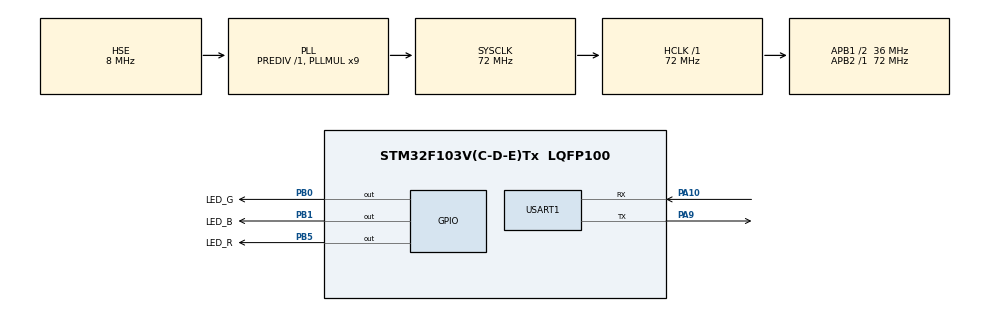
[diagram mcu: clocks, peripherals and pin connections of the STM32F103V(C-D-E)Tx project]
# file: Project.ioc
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Dma.Request0=USART1_RX
Dma.USART1_RX.0.Direction=DMA_PERIPH_TO_MEMORY
Dma.USART1_RX.0.Instance=DMA1_Channel5
Dma.USART1_RX.0.MemDataAlignment=DMA_MDATAALIGN_BYTE
Dma.USART1_RX.0.MemInc=DMA_MINC_ENABLE
Dma.USART1_RX.0.Mode=DMA_NORMAL
Dma.USART1_RX.0.PeriphDataAlignment=DMA_PDATAALIGN_BYTE
Dma.USART1_RX.0.PeriphInc=DMA_PINC_DISABLE
Dma.USART1_RX.0.Priority=DMA_PRIORITY_LOW
FREERTOS.Tasks01=defaultTask,0,128,StartDefaultTask,Default,NULL,Dynamic,NULL,NULL
Mcu.Family=STM32F1
Mcu.Name=STM32F103V(C-D-E)Tx
Mcu.Package=LQFP100
NVIC.DMA1_Channel5_IRQn=true\:5\:0\:false\:false\:true\:true\:false\:true\:true
NVIC.PriorityGroup=NVIC_PRIORITYGROUP_4
NVIC.TIM6_IRQn=true\:15\:0\:false\:false\:true\:false\:false\:true\:true
NVIC.TIM7_IRQn=true\:5\:0\:false\:false\:true\:true\:true\:true\:true
NVIC.TimeBase=TIM6_IRQn
NVIC.TimeBaseIP=TIM6
NVIC.USART1_IRQn=true\:5\:0\:false\:false\:true\:true\:true\:true\:true
OSC_IN.Mode=HSE-External-Oscillator
OSC_IN.Signal=RCC_OSC_IN
OSC_OUT.Mode=HSE-External-Oscillator
OSC_OUT.Signal=RCC_OSC_OUT
PA10.Mode=Asynchronous
PA10.Signal=USART1_RX
PA13.Mode=Serial_Wire
PA13.Signal=SYS_JTMS-SWDIO
PA14.Mode=Serial_Wire
PA14.Signal=SYS_JTCK-SWCLK
PA9.Mode=Asynchronous
PA9.Signal=USART1_TX
PB0.GPIO_Label=LED_G
PB0.PinState=GPIO_PIN_SET
PB0.Signal=GPIO_Output
PB1.GPIO_Label=LED_B
PB1.PinState=GPIO_PIN_SET
PB1.Signal=GPIO_Output
PB5.GPIO_Label=LED_R
PB5.PinState=GPIO_PIN_SET
PB5.Signal=GPIO_Output
ProjectManager.HeapSize=0x200
ProjectManager.StackSize=0x400
ProjectManager.TargetToolchain=CMake
RCC.AHBFreq_Value=72000000
RCC.APB1CLKDivider=RCC_HCLK_DIV2
RCC.APB1Freq_Value=36000000
RCC.APB1TimFreq_Value=72000000
RCC.APB2Freq_Value=72000000
RCC.APB2TimFreq_Value=72000000
RCC.HCLKFreq_Value=72000000
RCC.PLLMUL=RCC_PLL_MUL9
RCC.PLLSourceVirtual=RCC_PLLSOURCE_HSE
RCC.SYSCLKFreq_VALUE=72000000
RCC.SYSCLKSource=RCC_SYSCLKSOURCE_PLLCLK
RCC.USBFreq_Value=72000000
TIM7.AutoReloadPreload=TIM_AUTORELOAD_PRELOAD_ENABLE
TIM7.Period=1000-1
TIM7.Prescaler=72-1
USART1.VirtualMode=VM_ASYNC
VP_FREERTOS_VS_CMSIS_V1.Mode=CMSIS_V1
VP_SYS_VS_tim6.Mode=TIM6
VP_TIM7_VS_ClockSourceINT.Mode=Enable_Timer
board=custom

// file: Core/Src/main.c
/* USER CODE BEGIN Header */
/**
  ******************************************************************************
  * @file           : main.c
  * @brief          : Main program body
  ******************************************************************************
  * @attention
  *
  * Copyright (c) 2024 STMicroelectronics.
  * All rights reserved.
  *
  * This software is licensed under terms that can be found in the LICENSE file
  * in the root directory of this software component.
  * If no LICENSE file comes with this software, it is provided AS-IS.
  *
  ******************************************************************************
  */
/* USER CODE END Header */
#include "main.h"
#include "cmsis_os.h"
#include "dma.h"
#include "tim.h"
#include "usart.h"
#include "gpio.h"

void SystemClock_Config(void);
void MX_FREERTOS_Init(void);

int main(void)
{

  /* MCU Configuration--------------------------------------------------------*/

  /* Reset of all peripherals, Initializes the Flash interface and the Systick. */
  HAL_Init();

  /* Configure the system clock */
  SystemClock_Config();

  /* Initialize all configured peripherals */
  MX_GPIO_Init();
  MX_DMA_Init();
  MX_TIM7_Init();
  MX_USART1_UART_Init();

  /* Call init function for freertos objects (in cmsis_os2.c) */
  MX_FREERTOS_Init();

  /* Start scheduler */
  osKernelStart();

  /* We should never get here as control is now taken by the scheduler */

  /* Infinite loop */
  while (1)
  {

  }
}

void SystemClock_Config(void)
{
  RCC_OscInitTypeDef RCC_OscInitStruct = {0};
  RCC_ClkInitTypeDef RCC_ClkInitStruct = {0};

  /** Initializes the RCC Oscillators according to the specified parameters
  * in the RCC_OscInitTypeDef structure.
  */
  RCC_OscInitStruct.OscillatorType = RCC_OSCILLATORTYPE_HSE;
  RCC_OscInitStruct.HSEState = RCC_HSE_ON;
  RCC_OscInitStruct.HSEPredivValue = RCC_HSE_PREDIV_DIV1;
  RCC_OscInitStruct.HSIState = RCC_HSI_ON;
  RCC_OscInitStruct.PLL.PLLState = RCC_PLL_ON;
  RCC_OscInitStruct.PLL.PLLSource = RCC_PLLSOURCE_HSE;
  RCC_OscInitStruct.PLL.PLLMUL = RCC_PLL_MUL9;
  if (HAL_RCC_OscConfig(&RCC_OscInitStruct) != HAL_OK)
  {
    Error_Handler();
  }

  /** Initializes the CPU, AHB and APB buses clocks
  */
  RCC_ClkInitStruct.ClockType = RCC_CLOCKTYPE_HCLK|RCC_CLOCKTYPE_SYSCLK
                              |RCC_CLOCKTYPE_PCLK1|RCC_CLOCKTYPE_PCLK2;
  RCC_ClkInitStruct.SYSCLKSource = RCC_SYSCLKSOURCE_PLLCLK;
  RCC_ClkInitStruct.AHBCLKDivider = RCC_SYSCLK_DIV1;
  RCC_ClkInitStruct.APB1CLKDivider = RCC_HCLK_DIV2;
  RCC_ClkInitStruct.APB2CLKDivider = RCC_HCLK_DIV1;

  if (HAL_RCC_ClockConfig(&RCC_ClkInitStruct, FLASH_LATENCY_2) != HAL_OK)
  {
    Error_Handler();
  }
}

void HAL_TIM_PeriodElapsedCallback(TIM_HandleTypeDef *htim)
{
  if (htim->Instance == TIM6) {
    HAL_IncTick();
  }
}

void Error_Handler(void)
{
  __disable_irq();
  while (1)
  {
  }
}

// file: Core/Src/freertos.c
/* USER CODE BEGIN Header */
/**
 ******************************************************************************
 * File Name          : freertos.c
 * Description        : Code for freertos applications
 ******************************************************************************
 * @attention
 *
 * Copyright (c) 2024 STMicroelectronics.
 * All rights reserved.
 *
 * This software is licensed under terms that can be found in the LICENSE file
 * in the root directory of this software component.
 * If no LICENSE file comes with this software, it is provided AS-IS.
 *
 ******************************************************************************
 */
/* USER CODE END Header */

#include "FreeRTOS.h"
#include "task.h"
#include "main.h"
#include "cmsis_os.h"

/* USER CODE BEGIN Includes */
#include "app.h"
/* USER CODE END Includes */

osThreadId defaultTaskHandle;

void StartDefaultTask(void const *argument);

void MX_FREERTOS_Init(void); /* (MISRA C 2004 rule 8.1) */

/* GetIdleTaskMemory prototype (linked to static allocation support) */
void vApplicationGetIdleTaskMemory(StaticTask_t **ppxIdleTaskTCBBuffer,
    StackType_t **ppxIdleTaskStackBuffer, uint32_t *pulIdleTaskStackSize);

/* USER CODE BEGIN GET_IDLE_TASK_MEMORY */
static StaticTask_t xIdleTaskTCBBuffer;
static StackType_t xIdleStack[configMINIMAL_STACK_SIZE];

void vApplicationGetIdleTaskMemory(StaticTask_t **ppxIdleTaskTCBBuffer,
    StackType_t **ppxIdleTaskStackBuffer, uint32_t *pulIdleTaskStackSize)
{
    *ppxIdleTaskTCBBuffer   = &xIdleTaskTCBBuffer;
    *ppxIdleTaskStackBuffer = &xIdleStack[0];
    *pulIdleTaskStackSize   = configMINIMAL_STACK_SIZE;
    /* place for user code */
}
/* USER CODE END GET_IDLE_TASK_MEMORY */

void MX_FREERTOS_Init(void)
{
    /* USER CODE BEGIN Init */
    app_init();
    /* USER CODE END Init */

    /* Create the thread(s) */
    /* definition and creation of defaultTask */
    osThreadDef(defaultTask, StartDefaultTask, osPriorityNormal, 0, 128);
    defaultTaskHandle = osThreadCreate(osThread(defaultTask), NULL);

}

void StartDefaultTask(void const *argument)
{
    /* USER CODE BEGIN StartDefaultTask */
    /* Infinite loop */
    for (;;) { osDelay(200); }
    /* USER CODE END StartDefaultTask */
}
